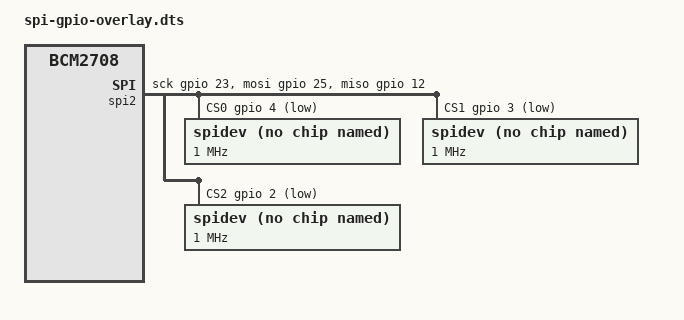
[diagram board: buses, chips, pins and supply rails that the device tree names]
/dts-v1/;
/plugin/;
/{
    compatible = "brcm,bcm2708";
    fragment@0 {
        target = <&spi2>;
        #address-cells = <1>;
        #size-cells = <0>;
        __overlay__ {
            compatible = "spi-gpio";
            #address-cells = <1>;
            #size-cells = <0>;
            ranges;
            gpio-mosi = <&gpio 25 0>;
            gpio-sck = <&gpio 23 0>;
            gpio-miso = <&gpio 12 >;
            cs-gpios = <&gpio 4 1>, <&gpio 3 1>, <&gpio 2 1>;
            num-chipselects = <3>;
            status = "ok";
            spidev@1{
                compatible = "spidev";
                reg = <0>;
                spi-max-frequency = <1000000>;
            };
            spidev@2{
                compatible = "spidev";
                reg = <1>;
                spi-max-frequency = <1000000>;
            };
            spidev@3{
                compatible = "spidev";
                reg = <2>;
                spi-max-frequency = <1000000>;
            };
        };
    };
};
